# M4KP register map
File version: 0.1
Registers are 32-bit, read-write, reset 0x0 unless marked. A register's access mark holds for its fields unless they carry their own. Offsets are from the block's base; [hi:lo] are bit positions; {n}, {i} and the like mark numbered series.

## CAN — CAN Controller (CAN)
Base 0x40005400
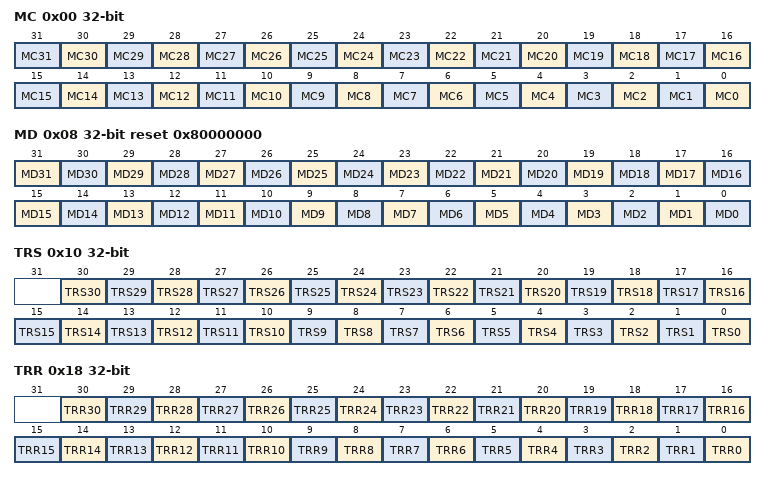
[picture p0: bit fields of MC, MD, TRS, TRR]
0x00 MC — CAN Mailbox Configuration Register
  [n] MC{n} (n=0..31)
0x08 MD reset 0x80000000 — CAN Mailbox Direction Register
  [31] MD31 ro, [n] MD{n} (n=0..30)
0x10 TRS — CAN Transmit Request Set Register
  [n] TRS{n} (n=0..30)
0x18 TRR — CAN Transmit Request Reset Register
  [n] TRR{n} (n=0..30)
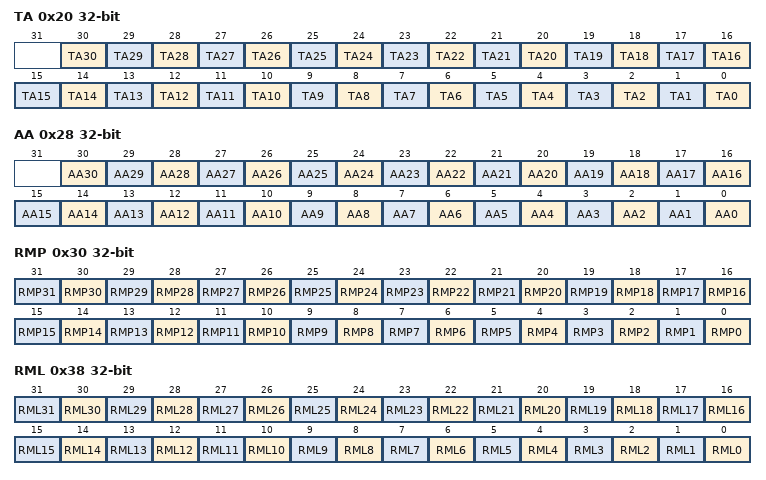
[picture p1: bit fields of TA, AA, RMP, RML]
0x20 TA — CAN Transmission Acknowledge Register
  [n] TA{n} (n=0..30)
0x28 AA — CAN Abort Acknowledge Register
  [n] AA{n} (n=0..30)
0x30 RMP — CAN Receive Message Pending Register
  [n] RMP{n} (n=0..31)
0x38 RML — CAN Receive Message Lost Register
  [n] RML{n} (n=0..31)
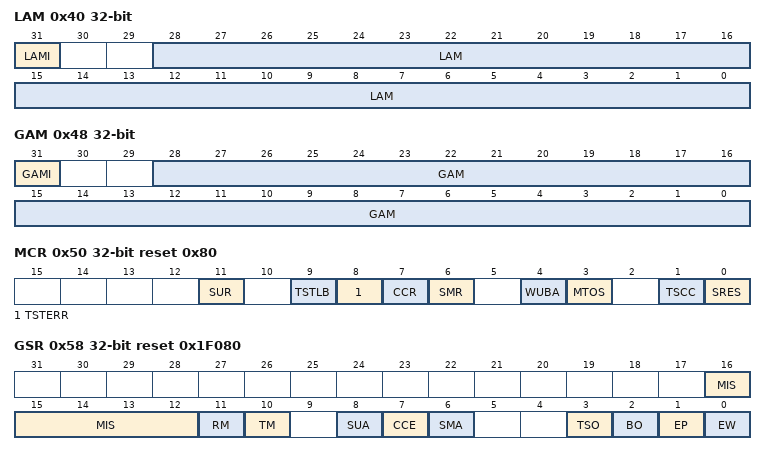
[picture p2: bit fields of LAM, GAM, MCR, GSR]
0x40 LAM — CAN Local Acceptance Mask Register
  [31] LAMI, [28:0] LAM
0x48 GAM — CAN Global Acceptance Mask Register
  [31] GAMI, [28:0] GAM
0x50 MCR reset 0x80 — CAN Master Control Register
  [11] SUR, [9] TSTLB, [8] TSTERR, [7] CCR, [6] SMR, [4] WUBA, [3] MTOS, [1] TSCC, [0] SRES
0x58 GSR ro reset 0x1F080 — CAN Global Status Register
  [16:12] MIS, [11] RM, [10] TM, [8] SUA, [7] CCE, [6] SMA, [3] TSO, [2] BO, [1] EP, [0] EW
0x60 BCR1 — CAN Bit Configuration Register 1
  [9:0] BRP
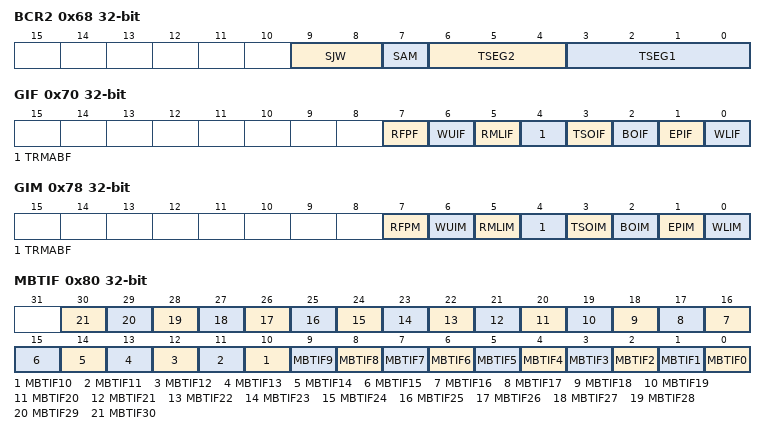
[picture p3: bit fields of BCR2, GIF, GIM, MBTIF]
0x68 BCR2 — CAN Bit Configuration Register 2
  [9:8] SJW, [7] SAM, [6:4] TSEG2, [3:0] TSEG1
0x70 GIF — CAN Global Interrupt Flag Register
  [7] RFPF, [6] WUIF, [5] RMLIF, [4] TRMABF, [3] TSOIF, [2] BOIF, [1] EPIF, [0] WLIF
0x78 GIM — CAN Global Interrupt Mask Register
  [7] RFPM, [6] WUIM, [5] RMLIM, [4] TRMABF, [3] TSOIM, [2] BOIM, [1] EPIM, [0] WLIM
0x80 MBTIF — CAN Mailbox Transmit Interrupt Flag Register
  [n] MBTIF{n} (n=0..30)
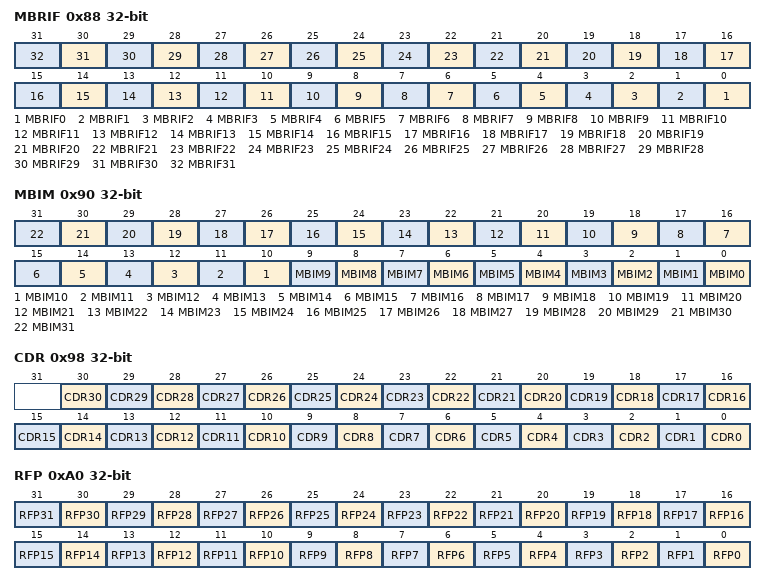
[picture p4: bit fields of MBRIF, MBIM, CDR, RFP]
0x88 MBRIF — CAN Mailbox Receive Interrupt Flag Register
  [n] MBRIF{n} (n=0..31)
0x90 MBIM — CAN Mailbox Interrupt Mask Register
  [n] MBIM{n} (n=0..31)
0x98 CDR — CAN Change Data Request
  [n] CDR{n} (n=0..30)
0xA0 RFP — CAN Remote Frame Pending Register
  [n] RFP{n} (n=0..31)
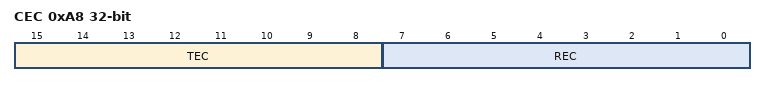
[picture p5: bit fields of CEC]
0xA8 CEC — CAN Error Counter Register
  [15:8] TEC, [7:0] REC
0xB0 TSP — CAN Time Stamp Counter Prescaler Register
  [3:0] TSP
0xB8 TSC ro — CAN Time Stamp Counter Register
  [15:0] TSC

## IA — Interrupt control A Register (IA)
Base 0x4003E000
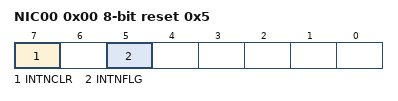
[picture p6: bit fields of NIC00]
0x00 NIC00 8-bit reset 0x5 — Non Maskable Interrupt Control Register(A) 00
  [7] INTNCLR wo, [5] INTNFLG ro

## RLM — Reset Low power Managiment Register (RLM)
Base 0x4003E400
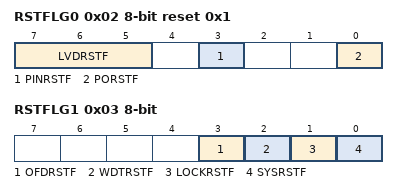
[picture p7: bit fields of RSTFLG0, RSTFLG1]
0x02 RSTFLG0 8-bit reset 0x1 (reset mask 0x1) — Reset flag register 0
  [7:5] LVDRSTF, [3] PINRSTF, [0] PORSTF
0x03 RSTFLG1 8-bit — Reset flag register 1
  [3] OFDRSTF, [2] WDTRSTF, [1] LOCKRSTF, [0] SYSRSTF

## LVD — Voltage detection circuit (LVD)
Base 0x4003EC00
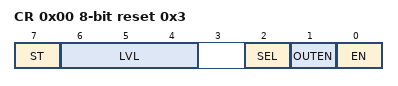
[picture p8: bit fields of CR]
0x00 CR 8-bit reset 0x3 — LVD Control register
  [7] ST ro, [6:4] LVL, [2] SEL, [1] OUTEN, [0] EN

## RPAR0 — RAM Parity (RAMP)
Base 0x40043000
Same registers: RPAR1 0x400A3000
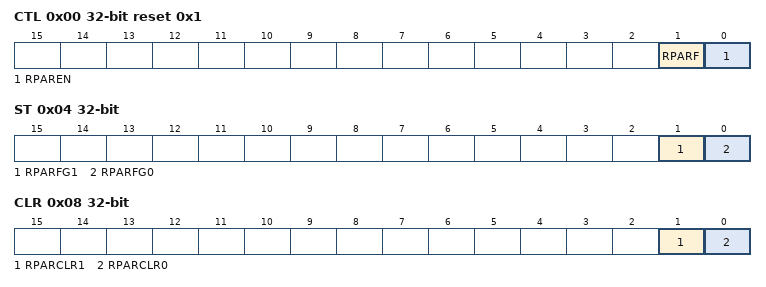
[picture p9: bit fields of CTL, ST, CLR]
0x00 CTL reset 0x1 — RAM Parity control register
  [1] RPARF, [0] RPAREN
0x04 ST ro — RAM Parity status register
  [1] RPARFG1, [0] RPARFG0
0x08 CLR wo — RAM Parity status clear register
  [1] RPARCLR1, [0] RPARCLR0
0x0C EAD0 ro — RAM Parity Error address register 0
  [31:0] RPAREADD0
0x10 EAD1 ro — RAM Parity Error address register 1
  [31:0] RPAREADD1

## CRC — CRC Calculation Circuit (CRC)
Base 0x40043100
0x00 DIN — CRC input data register
  [31:0] CRCDIN
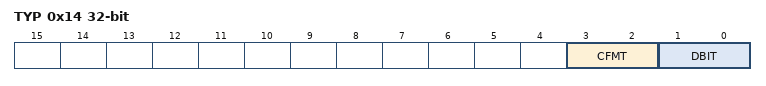
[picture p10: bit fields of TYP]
0x14 TYP — CRC data type register
  [3:2] CFMT, [1:0] DBIT
0x2C CLC reset 0xFFFFFFFF — CRC calculation result register
  [31:0] CRCCLC

## CG — Clock Control and Operation Mode (CG)
Base 0x40083000
0x00 PROTECT reset 0xC1
  [7:0] PROTECT
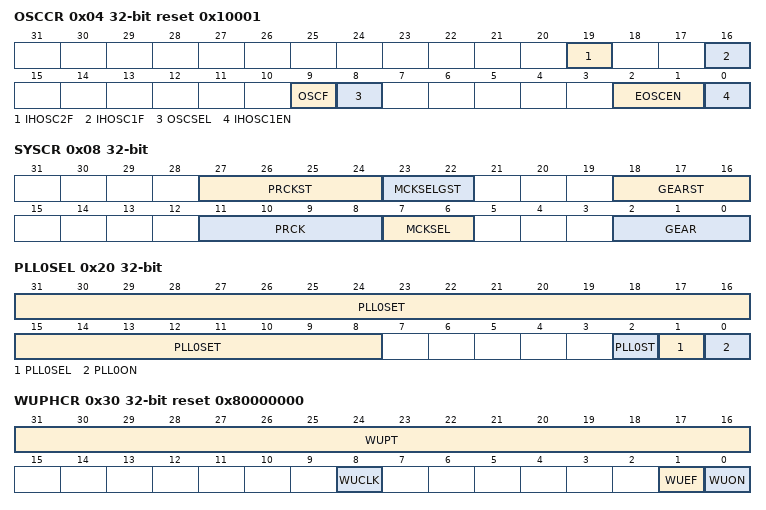
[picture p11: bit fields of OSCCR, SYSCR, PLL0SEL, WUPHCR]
0x04 OSCCR reset 0x10001 — Oscillation Control Register
  [19] IHOSC2F ro, [16] IHOSC1F ro, [9] OSCF ro, [8] OSCSEL, [2:1] EOSCEN, [0] IHOSC1EN
0x08 SYSCR — System Clock Control Register
  [27:24] PRCKST ro, [23:22] MCKSELGST ro, [18:16] GEARST ro, [11:8] PRCK, [7:6] MCKSEL, [2:0] GEAR
0x0C STBYCR — Standby Control Register
  [1:0] STBY
0x20 PLL0SEL — PLL Selection Register 0
  [31:8] PLL0SET, [2] PLL0ST ro, [1] PLL0SEL, [0] PLL0ON
0x30 WUPHCR reset 0x80000000 — High speed OSC Warming-up Register
  [31:16] WUPT, [8] WUCLK, [1] WUEF ro, [0] WUON wo
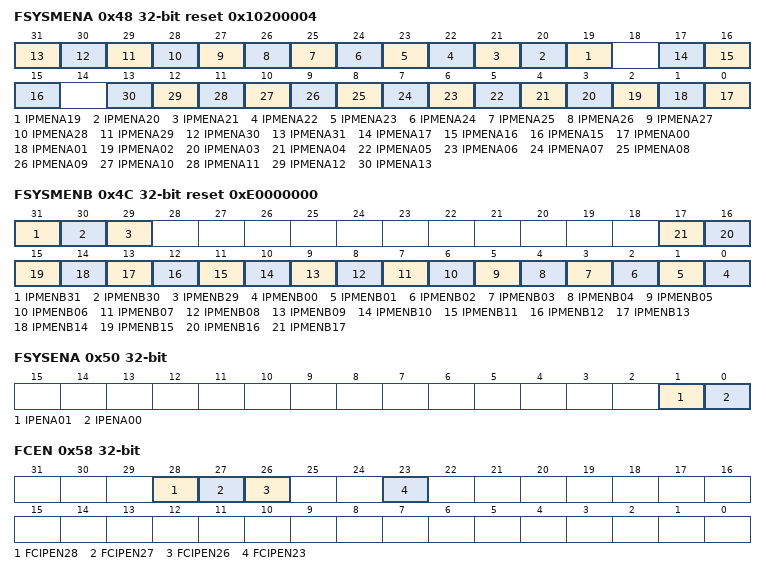
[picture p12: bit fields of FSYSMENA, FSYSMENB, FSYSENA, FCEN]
0x48 FSYSMENA reset 0x10200004 — Middle fsys Supply Stop Register A
  [n] IPMENA{n} (n=19..31), [17] IPMENA17, [16] IPMENA16, [15] IPMENA15, [n] IPMENA{n:02} (n=0..13)
0x4C FSYSMENB reset 0xE0000000 — Middle fsys Supply Stop Register B
  [31] IPMENB31, [30] IPMENB30, [29] IPMENB29, [n] IPMENB{n:02} (n=0..17)
0x50 FSYSENA — High fsys Supply Stop Register A
  [1] IPENA01, [0] IPENA00
0x58 FCEN — FC Supply Stop Register
  [28] FCIPEN28, [27] FCIPEN27, [26] FCIPEN26, [23] FCIPEN23
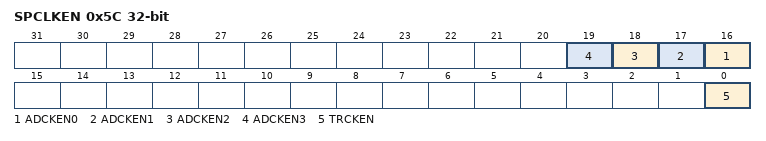
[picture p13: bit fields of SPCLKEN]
0x5C SPCLKEN — ADC_TRACE Clock Supply Stop Register
  [n+16] ADCKEN{n} (n=0..3), [0] TRCKEN
